AUTOSAR XML (schema 4-0-3)
package /ECU_Abstractions
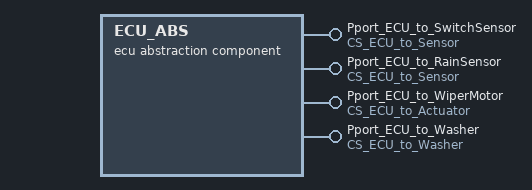
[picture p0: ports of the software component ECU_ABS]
  ecu abstraction sw component type ECU_ABS
    4 x provide port:
      Pport_ECU_to_SwitchSensor: provided-interface=CS_ECU_to_Sensor
      Pport_ECU_to_RainSensor: provided-interface=CS_ECU_to_Sensor
      Pport_ECU_to_WiperMotor: provided-interface=CS_ECU_to_Actuator
      Pport_ECU_to_Washer: provided-interface=CS_ECU_to_Washer
    behavior IB_ECU_ABS
      4 x operation invoked event:
        OIE_ECU_to_SwitchSensor: start-on-event=RE_ECU_to_SwitchSensor, operation=Pport_ECU_to_SwitchSensor.CS_Oper_ECU_to_SwitchSensor
        OIE_ECU_to_Wipermotor: start-on-event=RE_ECU_to_WiperMotor, operation=Pport_ECU_to_WiperMotor.CS_Oper_ECU_to_WiperMotor
        OperationInvokedEvent_0: start-on-event=RE_ECU_to_RainSensor, operation=Pport_ECU_to_RainSensor.CS_Oper_ECU_to_SwitchSensor
        OperationInvokedEvent_1: start-on-event=RE_ECU_to_Washer, operation=Pport_ECU_to_Washer.CS_Oper_ECU_to_Washer
      4 x runnable:
        RE_ECU_to_RainSensor
        RE_ECU_to_WiperMotor
        RE_ECU_to_SwitchSensor
        RE_ECU_to_Washer
package /Applications
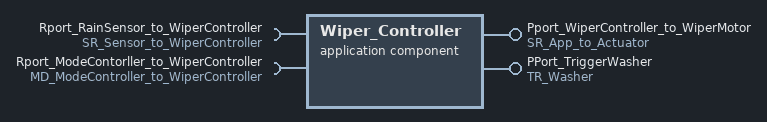
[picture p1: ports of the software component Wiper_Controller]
  application sw component type Wiper_Controller
    require port Rport_RainSensor_to_WiperController: required-interface=SR_Sensor_to_WiperController
    provide port Pport_WiperController_to_WiperMotor: provided-interface=SR_App_to_Actuator
    require port Rport_ModeContorller_to_WiperController: required-interface=MD_ModeController_to_WiperController
    provide port PPort_TriggerWasher: provided-interface=TR_Washer
    behavior IB_Wiper_Controller: data-type-mapping=ModeType
      5 x swc mode switch event, all with activation=ON-ENTRY:
        MSE_Mode_Auto: start-on-event=RE_Mode_Auto, mode=Rport_ModeContorller_to_WiperController.MDGP.Auto
          disabled-mode:
            Rport_ModeContorller_to_WiperController.MDGP.Wiper_Lv{1..3}
        MSE_Mode_Lv1: start-on-event=RE_Mode_Lv1, mode=Rport_ModeContorller_to_WiperController.MDGP.Wiper_Lv1
          disabled-mode:
            Rport_ModeContorller_to_WiperController.MDGP.Auto
            Rport_ModeContorller_to_WiperController.MDGP.Wiper_Lv2
            Rport_ModeContorller_to_WiperController.MDGP.Wiper_Lv3
        MSE_Mode_Lv2: start-on-event=RE_Mode_Lv2, mode=Rport_ModeContorller_to_WiperController.MDGP.Wiper_Lv2
          disabled-mode:
            Rport_ModeContorller_to_WiperController.MDGP.Auto
            Rport_ModeContorller_to_WiperController.MDGP.Wiper_Lv1
            Rport_ModeContorller_to_WiperController.MDGP.Wiper_Lv3
        MSE_Mode_Lv3: start-on-event=RE_Mode_Lv3, mode=Rport_ModeContorller_to_WiperController.MDGP.Wiper_Lv3
          disabled-mode:
            Rport_ModeContorller_to_WiperController.MDGP.Auto
            Rport_ModeContorller_to_WiperController.MDGP.Wiper_Lv1
            Rport_ModeContorller_to_WiperController.MDGP.Wiper_Lv2
        SwcModeSwitchEvent_0: start-on-event=RE_Trigger_Washer, mode=Rport_ModeContorller_to_WiperController.MDGP.Washer
      explicit-inter-runnable-variables:
        data Shared_Wiper_Speed: type=uint32
      implicit-inter-runnable-variables:
        data Shared_Wiper_Speeds: type=uint32
      5 x runnable:
        RE_Mode_Auto
          written-local-variables:
            access WrittenLocalVariables_VariableAccess_0: accessed-variable=Shared_Wiper_Speeds
            access WrittenLocalVariables_VariableAccess_1: accessed-variable=Shared_Wiper_Speed
        RE_Mode_Lv1
          written-local-variables:
            access WrittenLocalVariables_VariableAccess_0: accessed-variable=Shared_Wiper_Speeds
            access WrittenLocalVariables_VariableAccess_1: accessed-variable=Shared_Wiper_Speed
        RE_Mode_Lv2
          written-local-variables:
            access WrittenLocalVariables_VariableAccess_0: accessed-variable=Shared_Wiper_Speeds
            access WrittenLocalVariables_VariableAccess_1: accessed-variable=Shared_Wiper_Speed
        RE_Mode_Lv3
          written-local-variables:
            access WrittenLocalVariables_VariableAccess_0: accessed-variable=Shared_Wiper_Speeds
            access WrittenLocalVariables_VariableAccess_1: accessed-variable=Shared_Wiper_Speed
        RE_Trigger_Washer: external-triggering-point=PPort_TriggerWasher.TR_Washer
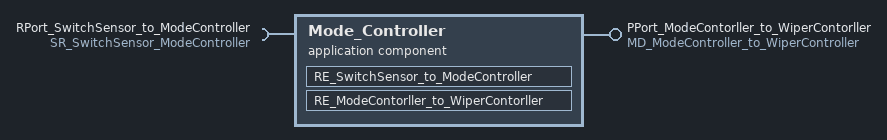
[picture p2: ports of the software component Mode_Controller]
  application sw component type Mode_Controller
    provide port PPort_ModeContorller_to_WiperContorller: provided-interface=MD_ModeController_to_WiperController
    require port RPort_SwitchSensor_to_ModeController: required-interface=SR_SwitchSensor_ModeController
    behavior IB_Mode_Controller: data-type-mapping=ModeType
      data received event DataReceivedEvent_0: start-on-event=RE_SwitchSensor_to_ModeController, data=RPort_SwitchSensor_to_ModeController.switch_sensor_value
      runnable RE_SwitchSensor_to_ModeController
        data-receive-point-by-arguments:
          access DRPA_switch_sensor_value_0: accessed-variable=RPort_SwitchSensor_to_ModeController.switch_sensor_value
      runnable RE_ModeContorller_to_WiperContorller
        mode switch point ModeSwitchPoint_0: mode-group=PPort_ModeContorller_to_WiperContorller.MDGP
package /Sensors_and_Actuators
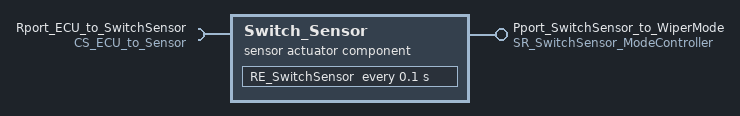
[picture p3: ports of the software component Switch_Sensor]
  sensor actuator sw component type Switch_Sensor
    require port Rport_ECU_to_SwitchSensor: required-interface=CS_ECU_to_Sensor
    provide port Pport_SwitchSensor_to_WiperMode: provided-interface=SR_SwitchSensor_ModeController
    behavior IB_Switch_Sensor
      timing event TE_100ms: start-on-event=RE_SwitchSensor, period=0.1
      runnable RE_SwitchSensor
        data-send-points:
          access DSP_switch_sensor_value_0: accessed-variable=Pport_SwitchSensor_to_WiperMode.switch_sensor_value
        sync call SynchronousServerCallPoint_0: operation=Rport_ECU_to_SwitchSensor.CS_Oper_ECU_to_SwitchSensor
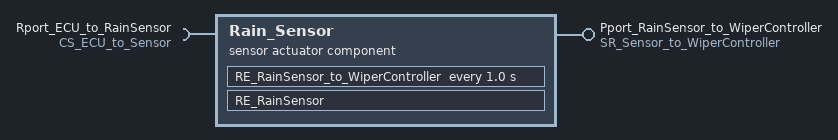
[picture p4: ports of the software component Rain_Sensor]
  sensor actuator sw component type Rain_Sensor
    require port Rport_ECU_to_RainSensor: required-interface=CS_ECU_to_Sensor
    provide port Pport_RainSensor_to_WiperController: provided-interface=SR_Sensor_to_WiperController
    behavior IB_Rain_Sensor
      timing event TimingEvent_0: start-on-event=RE_RainSensor_to_WiperController, period=1.0
      runnable RE_RainSensor
        sync call SynchronousServerCallPoint_0: operation=Rport_ECU_to_RainSensor.CS_Oper_ECU_to_SwitchSensor
      runnable RE_RainSensor_to_WiperController
        data-send-points:
          access DSP_rain_sensor_value_0: accessed-variable=Pport_RainSensor_to_WiperController.rain_sensor_value
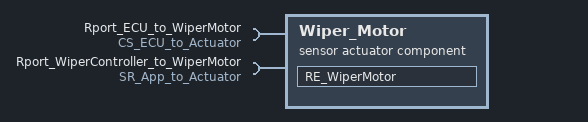
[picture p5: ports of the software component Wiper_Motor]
  sensor actuator sw component type Wiper_Motor
    require port Rport_ECU_to_WiperMotor: required-interface=CS_ECU_to_Actuator
    require port Rport_WiperController_to_WiperMotor: required-interface=SR_App_to_Actuator
    behavior IB_Wiper_Motor: supports-multiple-instantiation=true
      data received event DataReceivedEvent_0: start-on-event=RE_WiperMotor, data=Rport_WiperController_to_WiperMotor.wipermotor_Speed_Value
      runnable RE_WiperMotor
        data-receive-point-by-arguments:
          access DRPA_wipermotor_Speed_Value_0: accessed-variable=Rport_WiperController_to_WiperMotor.wipermotor_Speed_Value
        sync call SynchronousServerCallPoint_0: operation=Rport_ECU_to_WiperMotor.CS_Oper_ECU_to_WiperMotor
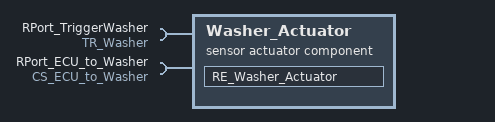
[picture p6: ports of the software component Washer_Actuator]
  sensor actuator sw component type Washer_Actuator
    require port RPort_TriggerWasher: required-interface=TR_Washer
    require port RPort_ECU_to_Washer: required-interface=CS_ECU_to_Washer
    behavior IB_Washer_Actuator
      external trigger occurred event ExternalTriggerOccurredEvent_0: start-on-event=RE_Washer_Actuator, trigger=RPort_TriggerWasher.TR_Washer
      runnable RE_Washer_Actuator
        sync call SynchronousServerCallPoint_0: operation=RPort_ECU_to_Washer.CS_Oper_ECU_to_Washer
